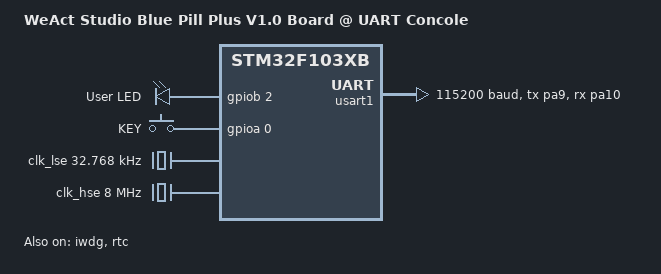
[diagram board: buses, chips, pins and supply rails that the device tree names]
/*
 * Copyright (c) 2024 TiaC Systems
 * SPDX-License-Identifier: Apache-2.0
 */

/dts-v1/;

#include <freq.h>
#include <mem.h>
#include <st/f1/stm32f103Xb.dtsi>
#include <st/f1/stm32f103c(8-b)tx-pinctrl.dtsi>
#include <zephyr/dt-bindings/gpio/gpio.h>
#include <zephyr/dt-bindings/input/input-event-codes.h>

/ {
	model = "WeAct Studio Blue Pill Plus V1.0 Board @ UART Concole";
	compatible = "weact,bluepill-f103cb", "weact,bluepill-f103cb-uartcons";

	chosen {
		zephyr,console = &usart1;
		zephyr,shell-uart = &usart1;
		zephyr,sram = &sram0;
		zephyr,flash = &flash0;
	};

	aliases {
		led0 = &user_led;
		sw0 = &user_button;
		watchdog0 = &iwdg;
	};

	gpio_leds {
		compatible = "gpio-leds";
		user_led: led {
			gpios = <&gpiob 2 GPIO_ACTIVE_HIGH>;
			label = "User LED";
		};
	};

	gpio_keys {
		compatible = "gpio-keys";
		user_button: button {
			label = "KEY";
			gpios = <&gpioa 0 (GPIO_ACTIVE_HIGH | GPIO_PULL_DOWN)>;
			zephyr,code = <INPUT_KEY_0>;
		};
	};
};

&clk_lse {
	status = "okay";
	clock-frequency = <32768>;
};

&clk_hse {
	status = "okay";
	clock-frequency = <DT_FREQ_M(8)>;
};

&pll {
	status = "okay";
	clocks = <&clk_hse>;
	mul = <9>;
	usbpre;
};

&rcc {
	clocks = <&pll>;
	clock-frequency = <DT_FREQ_M(72)>;
	ahb-prescaler = <1>;
	apb1-prescaler = <2>;
	apb2-prescaler = <1>;
	adc-prescaler = <6>;
};

&iwdg {
	status = "okay";
};

&rtc {
	status = "okay";
	clocks = <&rcc STM32_CLOCK_BUS_APB1 0x10000000>,
		 <&rcc STM32_SRC_LSE RTC_SEL(1)>;
};

&dma1 {
	status = "okay";
};

&flash0 {
	partitions {
		compatible = "fixed-partitions";
		#address-cells = <1>;
		#size-cells = <1>;

		/* Set 2KB of storage at the end of 128KB flash */
		storage_partition: partition@1f800 {
			label = "storage";
			reg = <0x0001f800 DT_SIZE_K(2)>;
		};
	};
};

&usart1 {
	status = "okay";
	pinctrl-0 = <&usart1_tx_pa9 &usart1_rx_pa10>;
	pinctrl-names = "default";
	current-speed = <115200>;
};

